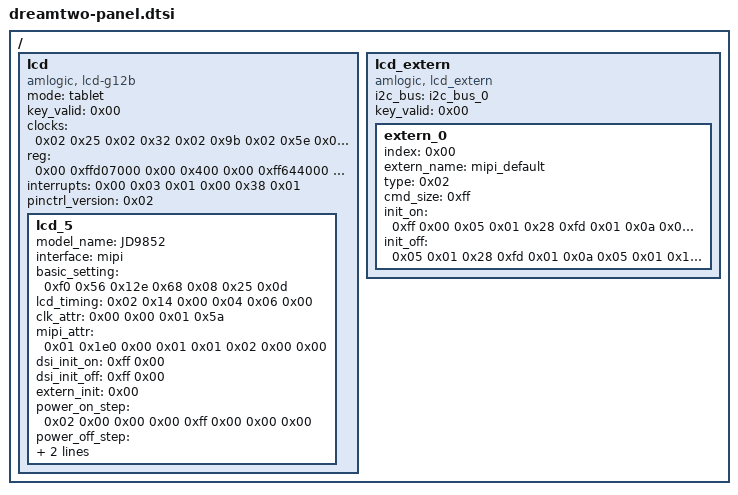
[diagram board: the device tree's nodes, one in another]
/ {
	lcd {
		compatible = "amlogic, lcd-g12b";
		mode = "tablet";
		status = "okay";
		key_valid = <0x00>;
		clocks = <0x02 0x25 0x02 0x32 0x02 0x9b 0x02 0x5e 0x02 0x60 0x02 0x07>;
		clock-names = "dsi_host_gate", "dsi_phy_gate", "dsi_meas", "encl_top_gate", "encl_int_gate", "gp0_pll";
		reg = <0x00 0xffd07000 0x00 0x400 0x00 0xff644000 0x00 0x200>;
		interrupts = <0x00 0x03 0x01 0x00 0x38 0x01>;
		interrupt-names = "vsync", "vsync2";
		pinctrl_version = <0x02>;

		lcd_5 {
			model_name = "JD9852";
			interface = "mipi";
			basic_setting = <0xf0 0x56 0x12e 0x68 0x08 0x25 0x0d>;
			lcd_timing = <0x02 0x14 0x00 0x04 0x06 0x00>;
			clk_attr = <0x00 0x00 0x01 0x5a>;
			mipi_attr = <0x01 0x1e0 0x00 0x01 0x01 0x02 0x00 0x00>;
			dsi_init_on = <0xff 0x00>;
			dsi_init_off = <0xff 0x00>;
			extern_init = <0x00>;
			power_on_step = <0x02 0x00 0x00 0x00 0xff 0x00 0x00 0x00>;
			power_off_step = <0x02 0x00 0x00 0x00 0xff 0x00 0x00 0x00>;
			backlight_index = <0xff>;
		};
	};

	lcd_extern {
		compatible = "amlogic, lcd_extern";
		status = "okay";
		i2c_bus = "i2c_bus_0";
		key_valid = <0x00>;

		extern_0 {
			index = <0x00>;
			extern_name = "mipi_default";
			status = "okay";
			type = <0x02>;
			cmd_size = <0xff>;
			init_on = <0xff 0x00 0x05 0x01 0x28 0xfd 0x01 0x0a 0x05 0x01 0x10 0xfd 0x01 0x0a 0x05 0x01 0x01 0xfd 0x01 0x0a 0xfd 0x01 0x69 0x29 0x04 0xdf 0x98 0x51 0xe9 0x23 0x02 0x36 0x41 0xfd 0x01 0x01 0x23 0x02 0x53 0x00 0x23 0x02 0x55 0x00 0x23 0x02 0xde 0x00 0xfd 0x01 0x01 0x29 0x05 0xb7 0x3c 0x93 0x3c 0x05 0x29 0x21 0xc8 0x3f 0x39 0x35 0x2d 0x2d 0x2f 0x2b 0x2c 0x2c 0x2d 0x2d 0x2a 0x29 0x2a 0x28 0x0e 0x3f 0x39 0x35 0x2d 0x2d 0x2f 0x2b 0x2d 0x2c 0x2d 0x2d 0x2a 0x29 0x29 0x28 0x0e 0x29 0x04 0xb9 0x33 0x08 0xcc 0x29 0x09 0xbb 0x46 0x7a 0x30 0x30 0x6c 0x60 0x50 0x70 0x29 0x03 0xbc 0x38 0x3c 0x29 0x03 0xc0 0x31 0x20 0x23 0x02 0xc1 0x16 0x29 0x12 0xc4 0x00 0xa0 0x79 0x0e 0x0a 0x16 0x79 0x0e 0x0a 0x16 0x79 0x0e 0x0a 0x16 0x82 0x00 0x03 0x29 0x07 0xd0 0x04 0x0c 0x6b 0x0f 0x01 0x03 0x29 0x03 0xd7 0x10 0x00 0x23 0x02 0x3a 0x65 0x29 0x05 0x2a 0x00 0x00 0x00 0xef 0x29 0x05 0x2b 0x00 0x00 0x00 0x55 0x23 0x02 0xde 0x02 0xfd 0x01 0x01 0x29 0x06 0xb8 0x1d 0xa0 0x2f 0x04 0x33 0x29 0x05 0xc1 0x10 0x66 0x66 0x01 0x23 0x02 0xde 0x02 0xfd 0x01 0x01 0x29 0x04 0xc5 0x4e 0x00 0x00 0xfd 0x01 0x01 0x29 0x04 0xca 0x30 0x20 0xf4 0xfd 0x01 0x01 0x23 0x02 0xde 0x04 0xfd 0x01 0x01 0x23 0x02 0xd3 0x3c 0xfd 0x01 0x01 0x23 0x02 0xde 0x00 0xfd 0x01 0x01 0x23 0x02 0x35 0x01 0x29 0x04 0xdf 0x00 0x00 0x00 0x29 0x01 0x21 0x05 0x01 0x11 0xfd 0x01 0x96 0x05 0x01 0x13 0x05 0x01 0x29 0xfd 0x01 0x3c 0xff 0x00>;
			init_off = <0x05 0x01 0x28 0xfd 0x01 0x0a 0x05 0x01 0x10 0xfd 0x01 0x96 0xff 0x00>;
		};
	};
};
